# AT32F405 register map
Vendor: Keil; Series: AT32F405; File version: 1.0
CPU: CM4 r0p1, little endian, no MPU, FPU, 4 interrupt priority bits
Registers are 32-bit, read-write, reset 0x0 unless marked. A register's access mark holds for its fields unless they carry their own. Offsets are from the block's base; [hi:lo] are bit positions; {n}, {i} and the like mark numbered series.

## PWC — Power control
Base 0x40007000
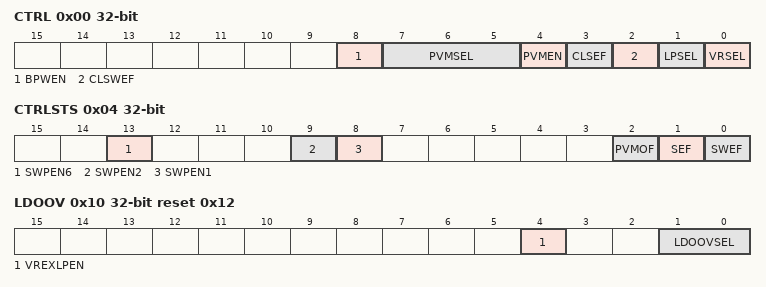
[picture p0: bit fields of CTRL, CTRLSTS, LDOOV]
0x00 CTRL — Power control register (PWC_CTRL)
  [8] BPWEN — Battery powered domain write enable
    0=Disabled (Battery powered domain write disabled); 1=Enabled (Battery powered domain write enabled)
  [7:5] PVMSEL — Power voltage monitoring boundary select
    1=v2_3 (2.3V); 2=v2_4 (2.4V); 3=v2_5 (2.5V); 4=v2_6 (2.6V); 5=v2_7 (2.7V); 6=v2_8 (2.8V); 7=v2_9 (2.9V)
  [4] PVMEN — Power voltage monitoring enable
    0=Disabled (Power voltage monitoring disabled); 1=Enabled (Power voltage monitoring enabled)
  [3] CLSEF wo write-1-clears — Clear SEF flag
    1=Clear the flag
  [2] CLSWEF wo write-1-clears — Clear SWEF flag
    1=Clear the flag
  [1] LPSEL — Low power mode select when Cortex-M4F sleepdeep
    0=Enter deepsleep mode when the CPU enters deepsleep mode; 1=Enter standby mode when the CPU enters deepsleep mode
  [0] VRSEL — Voltage regulator state select when deepsleep mode
    0=Enabled (LDO enabled in deepsleep mode); 1=Disabled (LDO disabled in deepsleep mode)
0x04 CTRLSTS — Power control and status register (PWC_CTRLSTS)
  [13] SWPEN6 — Standby wake-up pin 6 enable
    0=Disabled; 1=Enabled
  [9] SWPEN2 — Standby wake-up pin 2 enable
    0=Disabled; 1=Enabled
  [8] SWPEN1 — Standby wake-up pin 1 enable
    0=Disabled; 1=Enabled
  [2] PVMOF ro — Power voltage monitoring output flag
    0=Higher (Power voltage is higher than the threshold); 1=Lower (Power voltage is lower than the threshold)
  [1] SEF ro — Standby mode entry flag
    0=NoStandby (Device is not in standby mode); 1=Standby (Device is in standby mode)
  [0] SWEF ro — Standby wake-up event flag
    0=No wakeup event occurred; 1=Wakeup event occurred
0x10 LDOOV reset 0x12 — LDO output voltage register
  [4] VREXLPEN — Voltage regulator extra low power mode enable
  [1:0] LDOOVSEL — LDO output voltage select

## GPIOA — General purpose I/Os
Base 0x40020000
Same registers: GPIOB 0x40020400, GPIOC 0x40020800, GPIOD 0x40020C00, GPIOF 0x40021400
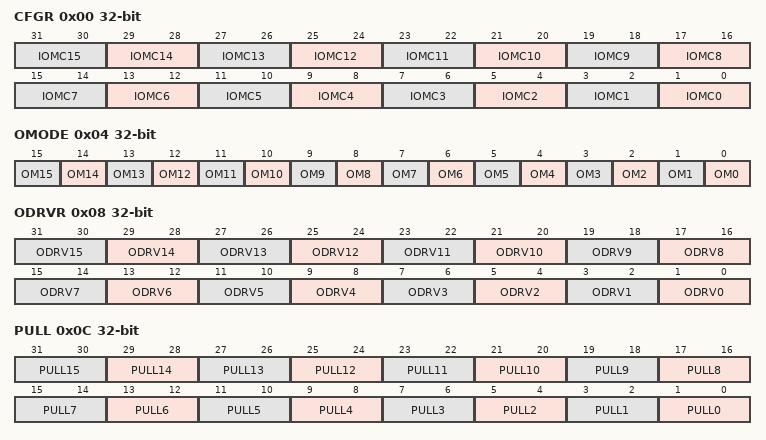
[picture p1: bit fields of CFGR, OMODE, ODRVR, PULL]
0x00 CFGR — GPIO function configurate register. **WARNING**: `reset()` writes the hardware reset value which does NOT account for SWD/JTAG pin default configuration. Calling `reset()` may disable debug access to the MCU.
  [2n+1:2n] IOMC{n} (n=0..15) — GPIOx pin {n} mode configurate
    0=Input mode; 1=Output (General-purpose output mode); 2=Multiplexed function mode; 3=Analog mode
0x04 OMODE — GPIO output mode register
  [n] OM{n} (n=0..15) — GPIOx pin {n} output mode configurate
    0=PushPull; 1=OpenDrain
0x08 ODRVR — GPIO drive capability register
  [2n+1:2n] ODRV{n} (n=0..15) — GPIOx pin {n} output drive capability
    1=Large sourcing/sinking strength; other=Normal sourcing/sinking strength
0x0C PULL — GPIO pull-up/pull-down register. **WARNING**: `reset()` writes the hardware reset value which does NOT account for SWD/JTAG pin default configuration. Calling `reset()` may disable debug access to the MCU.
  [2n+1:2n] PULL{n} (n=0..15) — GPIOx pin {n} pull configuration
    0=No pull-up/pull-down; 1=PullUp; 2=PullDown
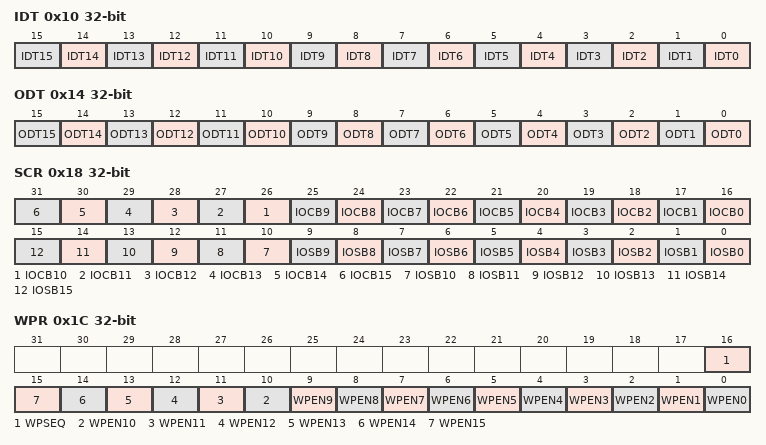
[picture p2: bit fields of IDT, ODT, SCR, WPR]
0x10 IDT ro — GPIO input data register
  [n] IDT{n} (n=0..15) — Port input data
    0=Low (Input is logic low); 1=High (Input is logic high)
0x14 ODT — GPIO output data register
  [n] ODT{n} (n=0..15) — Port output data
    on read: 0=PullDown; 1=PullUp | on write: 0=Low (Set output to logic low); 1=High (Set output to logic high)
0x18 SCR wo — Port bit set/clear register
  [n+16] IOCB{n} (n=0..15) write-1-clears — Clear bit {n}
    1=Clear the corresponding ODT bit
  [n] IOSB{n} (n=0..15) write-1-sets — Set bit {n}
    1=Set (Set the corresponding ODT bit)
0x1C WPR — Port write protect register
  [16] WPSEQ — Write protect sequence
    0=Clear; 1=Set
  [n] WPEN{n} (n=0..15) — Write protect enable {n}
    on read: 0=NotProtected (Port is not write protected); 1=Protected (Port is write protected) | on write: 0=NoProtect (No effect); 1=Protect (Write protect)
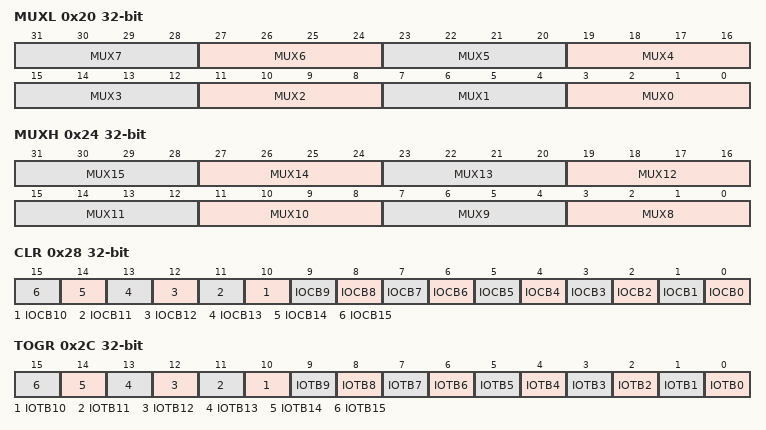
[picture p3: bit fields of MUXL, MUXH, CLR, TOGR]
0x20 MUXL — GPIO muxing function low register
  [4n+3:4n] MUX{n} (n=0..7) — GPIOx pin {n} muxing
0x24 MUXH — GPIO muxing function high register
  [4n-29:4n-32] MUX{n} (n=8..15) — GPIOx pin {n} muxing
0x28 CLR wo — GPIO bit reset register
  [n] IOCB{n} (n=0..15) write-1-clears — Clear bit {n}
    1=Clear the corresponding ODT bit
0x2C TOGR wo — GPIO bit toggle register
  [n] IOTB{n} (n=0..15) — toggle bit {n}
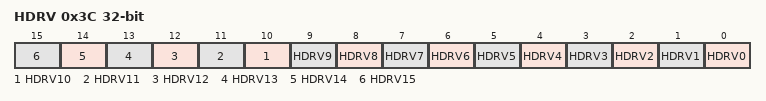
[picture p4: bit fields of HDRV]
0x3C HDRV — Huge current driver
  [n] HDRV{n} (n=0..15) — Port x driver bit y
    0=Normal/large drive strength (according to ODRVR); 1=Huge (GPIO is configured as maximum sourcing/sinking strength)
